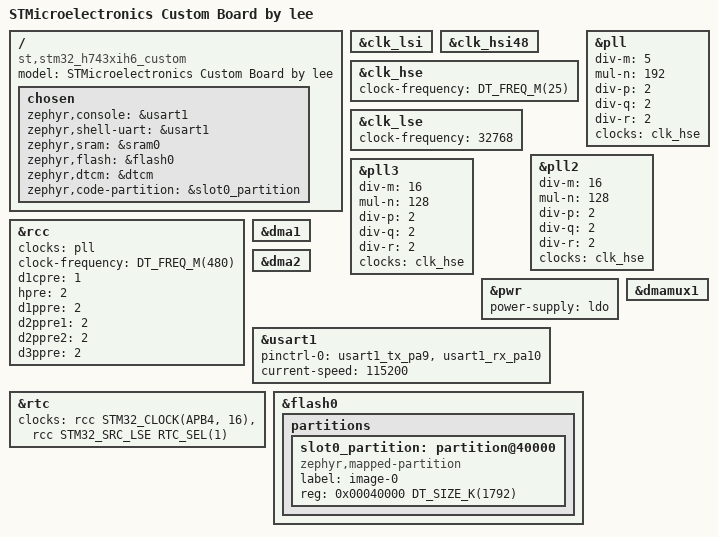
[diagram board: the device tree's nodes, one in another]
/*
 * Copyright (c) 2020 Teslabs Engineering S.L.
 *
 * SPDX-License-Identifier: Apache-2.0
 */

/dts-v1/;
#include <st/h7/stm32h743Xi.dtsi>
#include <st/h7/stm32h743xihx-pinctrl.dtsi>
#include <zephyr/dt-bindings/input/input-event-codes.h>

/ {
	model = "STMicroelectronics Custom Board by lee";
	compatible = "st,stm32_h743xih6_custom";

	chosen {
		zephyr,console = &usart1;
		zephyr,shell-uart = &usart1;
		zephyr,sram = &sram0;
		zephyr,flash = &flash0;
		zephyr,dtcm = &dtcm;
		zephyr,code-partition = &slot0_partition;
	};
};

&clk_lsi {
	status = "okay";
};

&clk_hsi48 {
	status = "okay";
};

&clk_hse {
	clock-frequency = <DT_FREQ_M(25)>;
	status = "okay";
};

&clk_lse {
	clock-frequency = <32768>;
	status = "okay";
};

&pll {
	div-m = <5>;
	mul-n = <192>;
	div-p = <2>;
	div-q = <2>;
	div-r = <2>;
	clocks = <&clk_hse>;
	status = "okay";
};

&pll2 {
	div-m = <16>;
	mul-n = <128>;
	div-p = <2>;
	div-q = <2>;
	div-r = <2>;
	clocks = <&clk_hse>;
	status = "okay";
};

&pll3 {
	div-m = <16>;
	mul-n = <128>;
	div-p = <2>;
	div-q = <2>;
	div-r = <2>;
	clocks = <&clk_hse>;
	status = "okay";
};

&rcc {
	clocks = <&pll>;
	clock-frequency = <DT_FREQ_M(480)>;
	d1cpre = <1>;
	hpre = <2>;
	d1ppre = <2>;
	d2ppre1 = <2>;
	d2ppre2 = <2>;
	d3ppre = <2>;
};

&pwr {
	power-supply = "ldo";
};

&dma1 {
	status = "okay";
};

&dma2 {
	status = "okay";
};

&dmamux1 {
	status = "okay";
};

&usart1 {
	pinctrl-0 = <&usart1_tx_pa9 &usart1_rx_pa10>;
	pinctrl-names = "default";
	current-speed = <115200>;
	status = "okay";
};

&rtc {
	clocks = <&rcc STM32_CLOCK(APB4, 16)>,
		 <&rcc STM32_SRC_LSE RTC_SEL(1)>;
	status = "okay";
};

&flash0 {
	partitions {
		#address-cells = <1>;
		#size-cells = <1>;
		ranges;

		/* 128KB for bootloader */
		slot0_partition: partition@40000 {
			compatible = "zephyr,mapped-partition";
			label = "image-0";
			reg = <0x00040000 DT_SIZE_K(1792)>;
		};
	};
};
